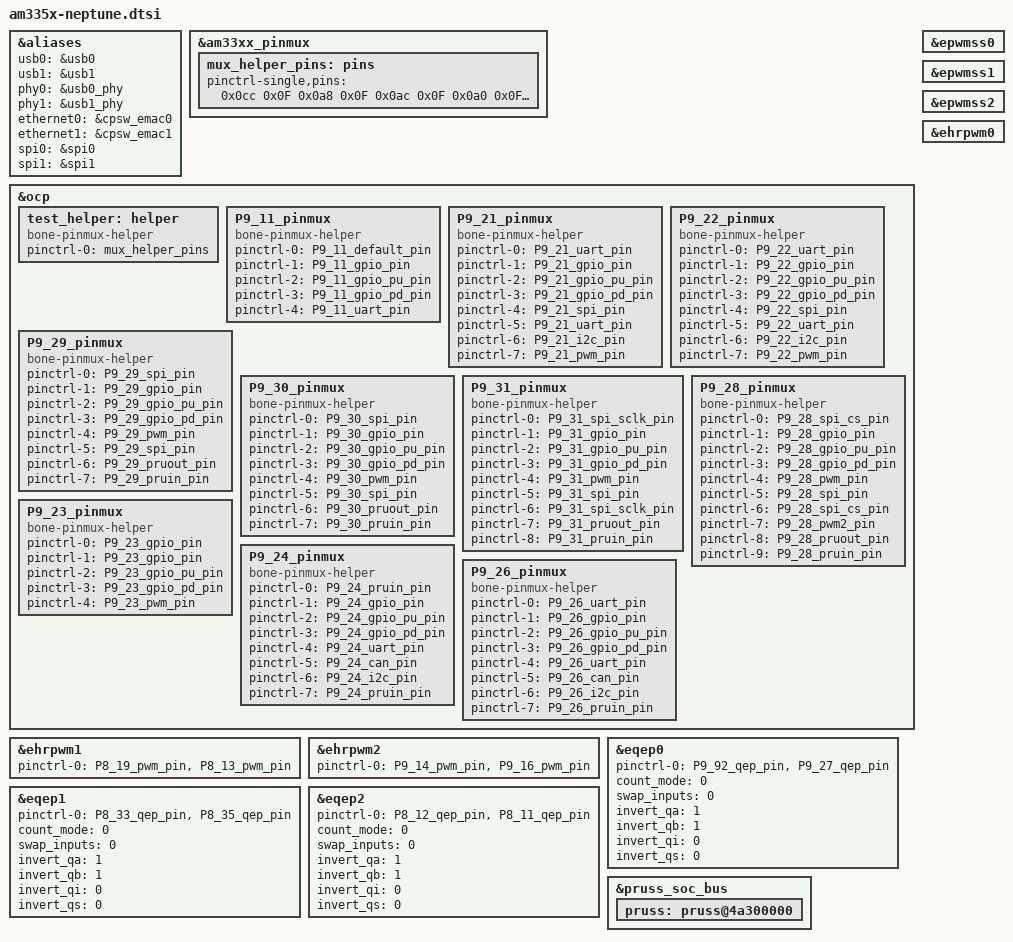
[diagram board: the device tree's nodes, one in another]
/*
 * @file am335x-neptune.dtsi
 *
 * used by:
 * am335x-boneblack-neptune.dts
 *
 *
 * @file am335x-boneblack-neptune.dtb
 *
 * based on am335x-boneblack.dtb
 *
 * This device tree serves to replace the need for an overlay when using the
 * MotorCape with piggybaked encoders. It is a stripped down and slightly
 * remapped version of am335x-roboticscape.dtsi.
 *
 * This file was updated in Feb 2021 to support the Neptune custom usage of the
 * Motor Cape.
 *
 */

&aliases {
	usb0 = &usb0;
	usb1 = &usb1;
	phy0 = &usb0_phy;
	phy1 = &usb1_phy;
	ethernet0 = &cpsw_emac0;
	ethernet1 = &cpsw_emac1;
	/* librobotcontrol expects /dev/spidev1 */
	spi0 = &spi0;
	spi1 = &spi1;
	/delete-property/ spi2;
};

/*******************************************************************************
* Pin Muxing
*******************************************************************************/
&am33xx_pinmux {

/*******************************************************************************
* Static Pinmux
*******************************************************************************/
	mux_helper_pins: pins {
		pinctrl-single,pins = <

			/* Motor Control GPIO Out*/
			0x0cc 0x0F	/*P8.34 MDIR_2B different from blue!!*/
			0x0a8 0x0F	/*P8.43 MDIR_3B*/
			0x0ac 0x0F	/*P8.44 MDIR_3A*/
			0x0a0 0x0F	/*P8.45 MDIR_4A*/
			0x0a4 0x0F	/*P8.46 MDIR_4B*/
			0x078 0x0F	/*P9.12 MDIR_1A different from blue!!*/
			0x074 0x0F	/*P9.13 MDIR_1B*/
			0x040 0x0F	/*P9.15 MDIR_2A*/
			0x1b4 0x0F	/*P9.41 MOT_STBY*/

			/* PRU encoder input */
			0x03c 0x36	/* P8_15,PRU0_r31_15,MODE6 */
			0x1ac 0x36	/* P9_25,PRU0_r31_7,MODE6 */

		>;
	};
};


/*******************************************************************************
* apply static and dynamic pinmux modes listed above. Configurable pins get the
* modes from am335x-boneblack-common-universal-pins.dtsi
*******************************************************************************/
&ocp {
	/* activate the static pinmux helper list of pin modes above */
	test_helper: helper {
		compatible = "bone-pinmux-helper";
		pinctrl-names = "default";
		pinctrl-0 = <&mux_helper_pins>;

		status = "okay";
	};

	/* UART4 RX DSM */
	P9_11_pinmux {
		compatible = "bone-pinmux-helper";
		status = "okay";
		pinctrl-names = "default", "gpio", "gpio_pu", "gpio_pd", "uart";
		pinctrl-0 = <&P9_11_default_pin>;
		pinctrl-1 = <&P9_11_gpio_pin>;
		pinctrl-2 = <&P9_11_gpio_pu_pin>;
		pinctrl-3 = <&P9_11_gpio_pd_pin>;
		pinctrl-4 = <&P9_11_uart_pin>;
	};

	/* UART 2 TX GPS*/
	P9_21_pinmux {
		compatible = "bone-pinmux-helper";
		status = "okay";
		pinctrl-names = "default", "gpio", "gpio_pu", "gpio_pd", "spi", "uart", "i2c", "pwm";
		pinctrl-0 = <&P9_21_uart_pin>;
		pinctrl-1 = <&P9_21_gpio_pin>;
		pinctrl-2 = <&P9_21_gpio_pu_pin>;
		pinctrl-3 = <&P9_21_gpio_pd_pin>;
		pinctrl-4 = <&P9_21_spi_pin>;
		pinctrl-5 = <&P9_21_uart_pin>;
		pinctrl-6 = <&P9_21_i2c_pin>;
		pinctrl-7 = <&P9_21_pwm_pin>;
	};

	/* UART 2 RX GPS */
	P9_22_pinmux {
		compatible = "bone-pinmux-helper";
		status = "okay";
		pinctrl-names = "default", "gpio", "gpio_pu", "gpio_pd", "spi", "uart", "i2c", "pwm";
		pinctrl-0 = <&P9_22_uart_pin>;
		pinctrl-1 = <&P9_22_gpio_pin>;
		pinctrl-2 = <&P9_22_gpio_pu_pin>;
		pinctrl-3 = <&P9_22_gpio_pd_pin>;
		pinctrl-4 = <&P9_22_spi_pin>;
		pinctrl-5 = <&P9_22_uart_pin>;
		pinctrl-6 = <&P9_22_i2c_pin>;
		pinctrl-7 = <&P9_22_pwm_pin>;
	};

	/* SPI MISO */
	P9_29_pinmux {
		compatible = "bone-pinmux-helper";
		status = "okay";
		pinctrl-names = "default", "gpio", "gpio_pu", "gpio_pd", "pwm", "spi", "pruout", "pruin";
		pinctrl-0 = <&P9_29_spi_pin>;
		pinctrl-1 = <&P9_29_gpio_pin>;
		pinctrl-2 = <&P9_29_gpio_pu_pin>;
		pinctrl-3 = <&P9_29_gpio_pd_pin>;
		pinctrl-4 = <&P9_29_pwm_pin>;
		pinctrl-5 = <&P9_29_spi_pin>;
		pinctrl-6 = <&P9_29_pruout_pin>;
		pinctrl-7 = <&P9_29_pruin_pin>;
	};

	/* SPI MOSI */
	P9_30_pinmux {
		compatible = "bone-pinmux-helper";
		status = "okay";
		pinctrl-names = "default", "gpio", "gpio_pu", "gpio_pd", "pwm", "spi", "pruout", "pruin";
		pinctrl-0 = <&P9_30_spi_pin>;
		pinctrl-1 = <&P9_30_gpio_pin>;
		pinctrl-2 = <&P9_30_gpio_pu_pin>;
		pinctrl-3 = <&P9_30_gpio_pd_pin>;
		pinctrl-4 = <&P9_30_pwm_pin>;
		pinctrl-5 = <&P9_30_spi_pin>;
		pinctrl-6 = <&P9_30_pruout_pin>;
		pinctrl-7 = <&P9_30_pruin_pin>;
	};

	/* SPI SCK */
	P9_31_pinmux {
		compatible = "bone-pinmux-helper";
		status = "okay";
		pinctrl-names = "default", "gpio", "gpio_pu", "gpio_pd", "pwm", "spi", "spi_sclk", "pruout", "pruin";
		pinctrl-0 = <&P9_31_spi_sclk_pin>;
		pinctrl-1 = <&P9_31_gpio_pin>;
		pinctrl-2 = <&P9_31_gpio_pu_pin>;
		pinctrl-3 = <&P9_31_gpio_pd_pin>;
		pinctrl-4 = <&P9_31_pwm_pin>;
		pinctrl-5 = <&P9_31_spi_pin>;
		pinctrl-6 = <&P9_31_spi_sclk_pin>;
		pinctrl-7 = <&P9_31_pruout_pin>;
		pinctrl-8 = <&P9_31_pruin_pin>;
	};

	/* SPI SS1 GPIO3_17*/
	P9_28_pinmux {
		compatible = "bone-pinmux-helper";
		status = "okay";
		pinctrl-names = "default", "gpio", "gpio_pu", "gpio_pd", "pwm", "spi", "spi_cs", "pwm2", "pruout", "pruin";
		pinctrl-0 = <&P9_28_spi_cs_pin>;
		pinctrl-1 = <&P9_28_gpio_pin>;
		pinctrl-2 = <&P9_28_gpio_pu_pin>;
		pinctrl-3 = <&P9_28_gpio_pd_pin>;
		pinctrl-4 = <&P9_28_pwm_pin>;
		pinctrl-5 = <&P9_28_spi_pin>;
		pinctrl-6 = <&P9_28_spi_cs_pin>;
		pinctrl-7 = <&P9_28_pwm2_pin>;
		pinctrl-8 = <&P9_28_pruout_pin>;
		pinctrl-9 = <&P9_28_pruin_pin>;
	};

	/* SPI SS1  GPIO1_17*/
	P9_23_pinmux {
		compatible = "bone-pinmux-helper";
		status = "okay";
		pinctrl-names = "default", "gpio", "gpio_pu", "gpio_pd", "pwm";
		pinctrl-0 = <&P9_23_gpio_pin>;
		pinctrl-1 = <&P9_23_gpio_pin>;
		pinctrl-2 = <&P9_23_gpio_pu_pin>;
		pinctrl-3 = <&P9_23_gpio_pd_pin>;
		pinctrl-4 = <&P9_23_pwm_pin>;
	};

	/* UART 1 TX */
	P9_24_pinmux {
		compatible = "bone-pinmux-helper";
		status = "okay";
		pinctrl-names = "default", "gpio", "gpio_pu", "gpio_pd", "uart", "can", "i2c",  "pruin";
		pinctrl-0 = <&P9_24_pruin_pin>;
		pinctrl-1 = <&P9_24_gpio_pin>;
		pinctrl-2 = <&P9_24_gpio_pu_pin>;
		pinctrl-3 = <&P9_24_gpio_pd_pin>;
		pinctrl-4 = <&P9_24_uart_pin>;
		pinctrl-5 = <&P9_24_can_pin>;
		pinctrl-6 = <&P9_24_i2c_pin>;
		pinctrl-7 = <&P9_24_pruin_pin>;
	};

	/* UART 1 RX */
	P9_26_pinmux {
		compatible = "bone-pinmux-helper";
		status = "okay";
		pinctrl-names = "default", "gpio", "gpio_pu", "gpio_pd", "uart", "can", "i2c",  "pruin";
		pinctrl-0 = <&P9_26_uart_pin>;
		pinctrl-1 = <&P9_26_gpio_pin>;
		pinctrl-2 = <&P9_26_gpio_pu_pin>;
		pinctrl-3 = <&P9_26_gpio_pd_pin>;
		pinctrl-4 = <&P9_26_uart_pin>;
		pinctrl-5 = <&P9_26_can_pin>;
		pinctrl-6 = <&P9_26_i2c_pin>;
		pinctrl-7 = <&P9_26_pruin_pin>;
	};


};


/*******************************************************************************
* PWMSS
*******************************************************************************/
&epwmss0 {
	status = "okay";
};

&epwmss1 {
	status = "okay";
};

&epwmss2 {
	status = "okay";
};

&ehrpwm0 {
	status = "okay";
};

&ehrpwm1 {
	pinctrl-names = "default";
	pinctrl-0 = <&P8_19_pwm_pin &P8_13_pwm_pin>;
	status = "okay";
};

&ehrpwm2 {
	pinctrl-names = "default";
	pinctrl-0 = <&P9_14_pwm_pin &P9_16_pwm_pin>;
	status = "okay";
};

/*******************************************************************************
* EQEP
*******************************************************************************/
&eqep0 {
	pinctrl-names = "default";
	pinctrl-0 = <&P9_92_qep_pin &P9_27_qep_pin>;

	count_mode = <0>;  /* 0 - Quadrature mode, normal 90 phase offset cha & chb.  1 - Direction mode.  cha input = clock, chb input = direction */
	swap_inputs = <0>; /* Are channel A and channel B swapped? (0 - no, 1 - yes) */
	invert_qa = <1>;   /* Should we invert the channel A input?  */
	invert_qb = <1>;   /* Should we invert the channel B input? I invert these because my encoder outputs drive transistors that pull down the pins */
	invert_qi = <0>;   /* Should we invert the index input? */
	invert_qs = <0>;   /* Should we invert the strobe input? */
	status = "okay";
};

&eqep1 {
	pinctrl-names = "default";
	pinctrl-0 = <&P8_33_qep_pin &P8_35_qep_pin>;

	count_mode = <0>;  /* 0 - Quadrature mode, normal 90 phase offset cha & chb.  1 - Direction mode.  cha input = clock, chb input = direction */
	swap_inputs = <0>; /* Are channel A and channel B swapped? (0 - no, 1 - yes) */
	invert_qa = <1>;   /* Should we invert the channel A input?  */
	invert_qb = <1>;   /* Should we invert the channel B input? I invert these because my encoder outputs drive transistors that pull down the pins */
	invert_qi = <0>;   /* Should we invert the index input? */
	invert_qs = <0>;   /* Should we invert the strobe input? */
	status = "okay";
};

&eqep2 {
	pinctrl-names = "default";
	pinctrl-0 = <&P8_12_qep_pin &P8_11_qep_pin>;

	count_mode = <0>;  /* 0 - Quadrature mode, normal 90 phase offset cha & chb.  1 - Direction mode.  cha input = clock, chb input = direction */
	swap_inputs = <0>; /* Are channel A and channel B swapped? (0 - no, 1 - yes) */
	invert_qa = <1>;   /* Should we invert the channel A input?  */
	invert_qb = <1>;   /* Should we invert the channel B input? I invert these because my encoder outputs drive transistors that pull down the pins */
	invert_qi = <0>;   /* Should we invert the index input? */
	invert_qs = <0>;   /* Should we invert the strobe input? */
	status = "okay";
};



/*******************************************************************************
* PRU Encoder and Servos
*******************************************************************************/
&pruss_soc_bus {
	status = "okay";

	pruss: pruss@4a300000 {
		status = "okay";
	};
};
